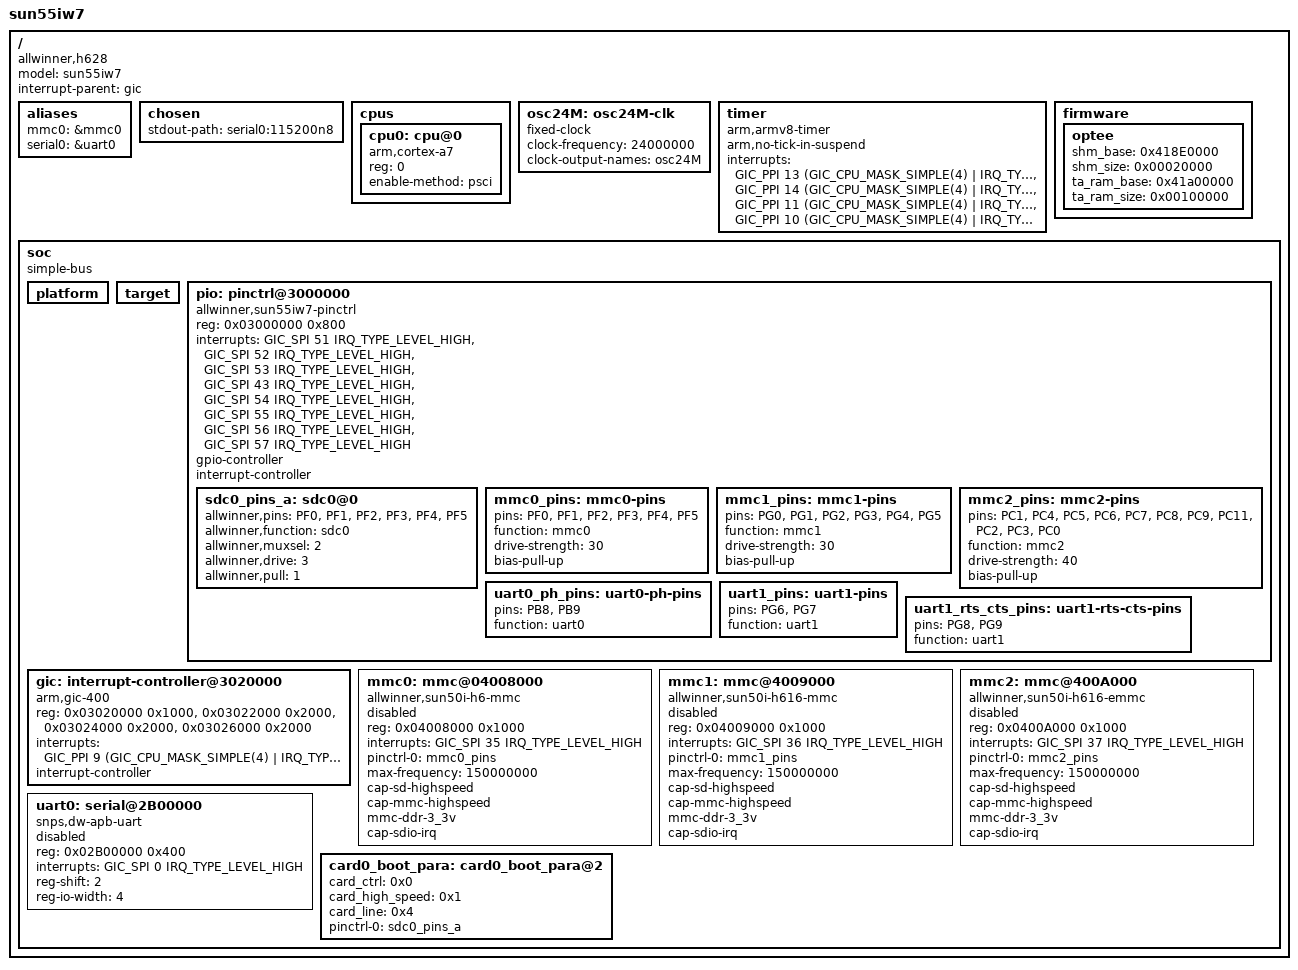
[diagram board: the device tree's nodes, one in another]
/* SPDX-License-Identifier: GPL-2.0+ */
/*
 * Allwinner Technology CO., Ltd. sun55iw7p1 platform
 *
 * modify base on juno.dts
 */
/dts-v1/;

#include <dt-bindings/interrupt-controller/arm-gic.h>
#include <dt-bindings/gpio/gpio.h>
#include <dt-bindings/interrupt-controller/arm-gic.h>

/ {
	model = "sun55iw7";
	compatible = "allwinner,h628", "arm,sun55iw7p1";
	interrupt-parent = <&gic>;
	#address-cells = <2>;
	#size-cells = <2>;

	aliases {
		mmc0 = &mmc0;
		serial0 = &uart0;
	};

	chosen {
		stdout-path = "serial0:115200n8";
	};

	cpus {
		#address-cells = <1>;
		#size-cells = <0>;

		cpu0: cpu@0 {
			compatible = "arm,cortex-a7";
			device_type = "cpu";
			reg = <0>;
			enable-method = "psci";
		};
	};

	osc24M: osc24M-clk {
		#clock-cells = <0>;
		compatible = "fixed-clock";
		clock-frequency = <24000000>;
		clock-output-names = "osc24M";
	};

	timer {
		compatible = "arm,armv8-timer";
		arm,no-tick-in-suspend;
		interrupts = <GIC_PPI 13
			(GIC_CPU_MASK_SIMPLE(4) | IRQ_TYPE_LEVEL_HIGH)>,
			     <GIC_PPI 14
			(GIC_CPU_MASK_SIMPLE(4) | IRQ_TYPE_LEVEL_HIGH)>,
			     <GIC_PPI 11
			(GIC_CPU_MASK_SIMPLE(4) | IRQ_TYPE_LEVEL_HIGH)>,
			     <GIC_PPI 10
			(GIC_CPU_MASK_SIMPLE(4) | IRQ_TYPE_LEVEL_HIGH)>;
	};

	firmware {
		optee {
			shm_base = <0x418E0000>;
			shm_size = <0x00020000>;
			ta_ram_base = <0x41a00000>;
			ta_ram_size = <0x00100000>;
			/* trace_level = <0x4>; */
		};
	};

	soc {
		compatible = "simple-bus";
		#address-cells = <1>;
		#size-cells = <1>;
		ranges = <0x0 0x0 0x0 0x40000000>;

		platform:platform {
			device_type = "platform";
		};

		target:target {
			device_type = "target";
		};

		pio: pinctrl@3000000 {
			compatible = "allwinner,sun55iw7-pinctrl";
			reg = <0x03000000 0x800>;
			interrupts = <GIC_SPI 51 IRQ_TYPE_LEVEL_HIGH>,
				     <GIC_SPI 52 IRQ_TYPE_LEVEL_HIGH>,
				     <GIC_SPI 53 IRQ_TYPE_LEVEL_HIGH>,
				     <GIC_SPI 43 IRQ_TYPE_LEVEL_HIGH>,
				     <GIC_SPI 54 IRQ_TYPE_LEVEL_HIGH>,
				     <GIC_SPI 55 IRQ_TYPE_LEVEL_HIGH>,
				     <GIC_SPI 56 IRQ_TYPE_LEVEL_HIGH>,
				     <GIC_SPI 57 IRQ_TYPE_LEVEL_HIGH>;
			gpio-controller;
			#gpio-cells = <3>;
			interrupt-controller;
			#interrupt-cells = <3>;

			sdc0_pins_a: sdc0@0 {
				allwinner,pins = "PF0", "PF1", "PF2",
						"PF3", "PF4", "PF5";
				allwinner,function = "sdc0";
				allwinner,muxsel = <2>;
				allwinner,drive = <3>;
				allwinner,pull = <1>;
			};

			mmc0_pins: mmc0-pins {
				pins = "PF0", "PF1", "PF2", "PF3",
				       "PF4", "PF5";
				function = "mmc0";
				drive-strength = <30>;
				bias-pull-up;
			};

			/* omit-if-no-ref */
			mmc1_pins: mmc1-pins {
				pins = "PG0", "PG1", "PG2", "PG3",
				       "PG4", "PG5";
				function = "mmc1";
				drive-strength = <30>;
				bias-pull-up;
			};

			mmc2_pins: mmc2-pins {
				pins = "PC1", "PC4", "PC5", "PC6",
					"PC7", "PC8", "PC9",
					"PC11", "PC2", "PC3", "PC0";
				function = "mmc2";
				drive-strength = <40>;
				bias-pull-up;
			};

			uart0_ph_pins: uart0-ph-pins {
				pins = "PB8", "PB9";
				function = "uart0";
			};

			/* omit-if-no-ref */
			uart1_pins: uart1-pins {
				pins = "PG6", "PG7";
				function = "uart1";
			};

			/* omit-if-no-ref */
			uart1_rts_cts_pins: uart1-rts-cts-pins {
				pins = "PG8", "PG9";
				function = "uart1";
			};
		};

		gic: interrupt-controller@3020000 {
			compatible = "arm,gic-400";
			reg = <0x03020000 0x1000>,
			      <0x03022000 0x2000>,
			      <0x03024000 0x2000>,
			      <0x03026000 0x2000>;
			interrupts = <GIC_PPI 9 (GIC_CPU_MASK_SIMPLE(4) | IRQ_TYPE_LEVEL_HIGH)>;
			interrupt-controller;
			#interrupt-cells = <3>;
		};

		mmc0: mmc@04008000 {
			compatible = "allwinner,sun50i-h6-mmc";
			reg = <0x04008000 0x1000>;
			interrupts = <GIC_SPI 35 IRQ_TYPE_LEVEL_HIGH>;
			pinctrl-names = "default";
			pinctrl-0 = <&mmc0_pins>;
			status = "disabled";
			max-frequency = <150000000>;
			cap-sd-highspeed;
			cap-mmc-highspeed;
			mmc-ddr-3_3v;
			cap-sdio-irq;
			#address-cells = <1>;
			#size-cells = <0>;
		};

		mmc1: mmc@4009000 {
			compatible = "allwinner,sun50i-h616-mmc",
				     "allwinner,sun50i-a100-mmc";
			reg = <0x04009000 0x1000>;
			interrupts = <GIC_SPI 36 IRQ_TYPE_LEVEL_HIGH>;
			pinctrl-names = "default";
			pinctrl-0 = <&mmc1_pins>;
			status = "disabled";
			max-frequency = <150000000>;
			cap-sd-highspeed;
			cap-mmc-highspeed;
			mmc-ddr-3_3v;
			cap-sdio-irq;
			#address-cells = <1>;
			#size-cells = <0>;
		};

		mmc2: mmc@400A000 {
			compatible = "allwinner,sun50i-h616-emmc",
				     "allwinner,sun50i-a100-emmc";
			reg = <0x0400A000 0x1000>;
			interrupts = <GIC_SPI 37 IRQ_TYPE_LEVEL_HIGH>;
			pinctrl-names = "default";
			pinctrl-0 = <&mmc2_pins>;
			status = "disabled";
			max-frequency = <150000000>;
			cap-sd-highspeed;
			cap-mmc-highspeed;
			mmc-ddr-3_3v;
			cap-sdio-irq;
			#address-cells = <1>;
			#size-cells = <0>;
		};

		uart0: serial@2B00000 {
			compatible = "snps,dw-apb-uart";
			reg = <0x02B00000 0x400>;
			interrupts = <GIC_SPI 0 IRQ_TYPE_LEVEL_HIGH>;
			reg-shift = <2>;
			reg-io-width = <4>;
			status = "disabled";
		};

		card0_boot_para:card0_boot_para@2 {
			device_type = "card0_boot_para";
			/* reg = <0x0 0x2 0x0 0x0>;  [> Avoid dtc compiling warnings. @TODO: Developer should modify this to the actual value <] */
			card_ctrl = <0x0>;
			card_high_speed = <0x1>;
			card_line = <0x4>;
			pinctrl-0 = <&sdc0_pins_a>;
		};
	};
};

#include ".board-uboot.dts"
